# R7FA2E307 register map
Vendor: Renesas Electronics Corporation; Series: RA2; File version: 1.20.00
CPU: CM23 r1p0, little endian, MPU, no FPU, VTOR, 2 interrupt priority bits, 32 interrupts
Registers are 8-bit, read-write, reset 0x0 unless marked. A register's access mark holds for its fields unless they carry their own. Offsets are from the block's base; [hi:lo] are bit positions; {n}, {i} and the like mark numbered series; 'fields as' and 'values as' point back to an identical list.

## RMPU — Renesas Memory Protection Unit
Base 0x40000000
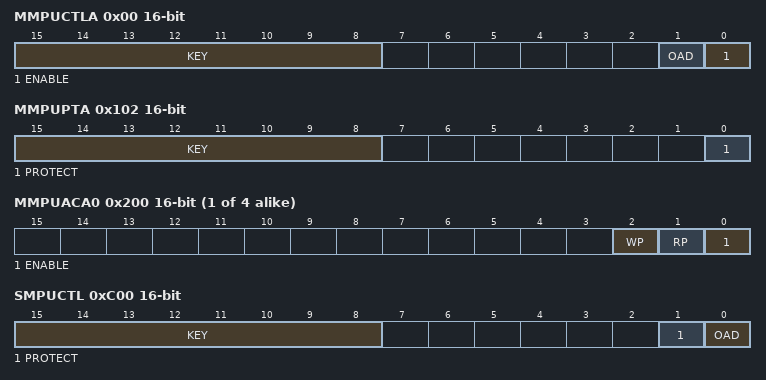
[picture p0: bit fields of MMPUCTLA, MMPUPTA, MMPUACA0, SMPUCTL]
0x00 MMPUCTLA 16-bit — Bus Master MPU Control Register
  [15:8] KEY — Key Code
  [1] OAD — Operation After Detection
  [0] ENABLE — Master Group Enable
0x102 MMPUPTA 16-bit — Group A Protection of Register
  [15:8] KEY — Key Code
  [0] PROTECT — Protection of Register
{0x200+0x10*i} MMPUACA{i} (i=0..3) 16-bit — Group A Region {i} access control register
  [2] WP — Write Protection
  [1] RP — Read Protection
  [0] ENABLE — Region Enable
{0x204+0x10*i} MMPUSA{i} (i=0..3) 32-bit (reset mask 0x3) — Group A Region {i} Start Address Register
  [31:0] MMPUSA — Region Start Address
{0x208+0x10*i} MMPUEA{i} (i=0..3) 32-bit reset 0x3 (reset mask 0x3) — Group A Region {i} End Address Register
  [31:0] MMPUEA — Region End Address
0xC00 SMPUCTL 16-bit — Slave MPU Control Register
  [15:8] KEY — Key Code
  [1] PROTECT — Protection of Register
  [0] OAD — Operation After Detection
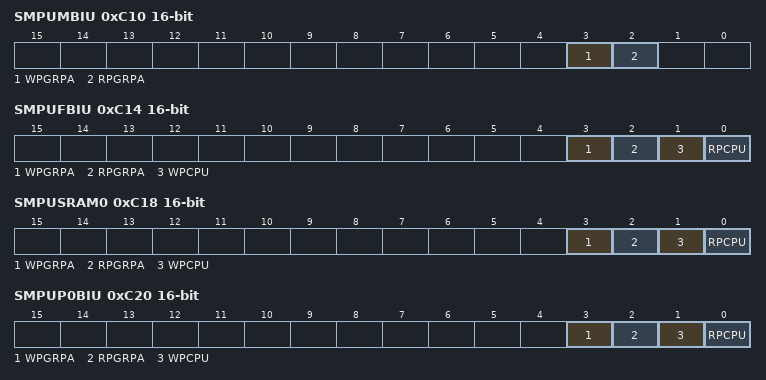
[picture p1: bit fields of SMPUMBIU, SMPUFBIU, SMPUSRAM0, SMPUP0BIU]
0xC10 SMPUMBIU 16-bit — Access Control Register for Memory Bus 1
  [3] WPGRPA — Master MPU Group A Write Protection
  [2] RPGRPA — Master MPU Group A Read Protection
0xC14 SMPUFBIU 16-bit — Access Control Register for Internal Peripheral Bus 9
  [3] WPGRPA — Master MPU Group A Write Protection
  [2] RPGRPA — Master MPU Group A Read Protection
  [1] WPCPU — CPU Write Protection
  [0] RPCPU — CPU Read Protection
0xC18 SMPUSRAM0 16-bit — Access Control Register for Memory Bus 4
  fields as SMPUFBIU
0xC20 SMPUP0BIU 16-bit — Access Control Register for Internal Peripheral Bus 1
  fields as SMPUFBIU
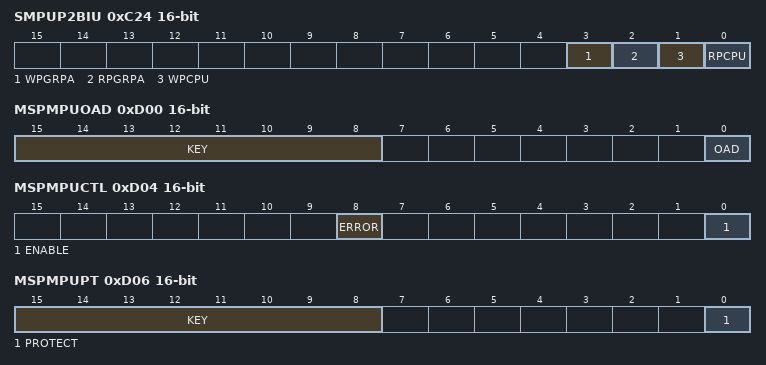
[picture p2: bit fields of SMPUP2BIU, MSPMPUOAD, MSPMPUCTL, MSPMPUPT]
0xC24 SMPUP2BIU 16-bit — Access Control Register for Internal Peripheral Bus 3
  fields as SMPUFBIU
0xD00 MSPMPUOAD 16-bit — Stack Pointer Monitor Operation After Detection Register
  [15:8] KEY — Key Code
  [0] OAD — Operation after Detection
0xD04 MSPMPUCTL 16-bit (reset mask 0xFEFF) — Stack Pointer Monitor Access Control Register
  [8] ERROR — Stack Pointer Monitor Error Flag
  [0] ENABLE — Stack Pointer Monitor Enable
0xD06 MSPMPUPT 16-bit — Stack Pointer Monitor Protection Register
  [15:8] KEY — Key Code
  [0] PROTECT — Protection of Register
0xD08 MSPMPUSA 32-bit reset not defined — Main Stack Pointer (MSP) Monitor Start Address Register
  [31:0] MSPMPUSA range 0x1FF00000..0x200FFFFC — Region Start Address
0xD0C MSPMPUEA 32-bit reset not defined — Main Stack Pointer (MSP) Monitor End Address Register
  [31:0] MSPMPUEA range 0x1FF00003..0x200FFFFF — Region End Address
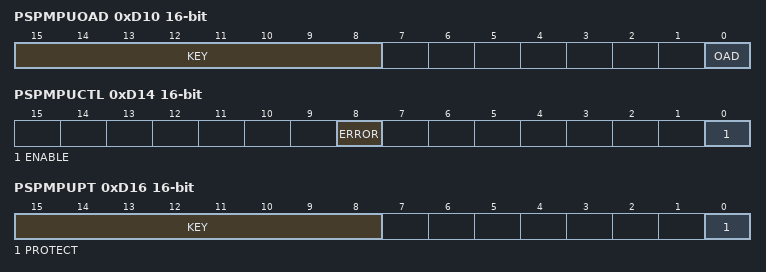
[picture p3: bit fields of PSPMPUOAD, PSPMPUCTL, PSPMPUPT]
0xD10 PSPMPUOAD 16-bit — Stack Pointer Monitor Operation After Detection Register
  [15:8] KEY — Key Code
  [0] OAD — Operation after Detection
0xD14 PSPMPUCTL 16-bit (reset mask 0xFEFF) — Stack Pointer Monitor Access Control Register
  fields as MSPMPUCTL
0xD16 PSPMPUPT 16-bit — Stack Pointer Monitor Protection Register
  [15:8] KEY — Key Code
  [0] PROTECT — Protection of Register
0xD18 PSPMPUSA 32-bit reset not defined — Process Stack Pointer (PSP) Monitor Start Address Register
  [31:0] PSPMPUSA range 0x1FF00000..0x200FFFFC — Region Start Address
0xD1C PSPMPUEA 32-bit reset not defined — Process Stack Pointer (PSP) Monitor End Address Register
  [31:0] PSPMPUEA range 0x1FF00003..0x200FFFFF — Region End Address

## SRAM — SRAM Control
Base 0x40002000
0x00 PARIOAD — SRAM Parity Error Operation After Detection Register
  [0] OAD — Operation After Detection
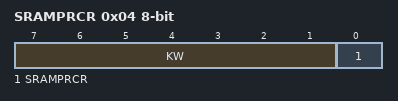
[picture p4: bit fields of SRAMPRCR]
0x04 SRAMPRCR — SRAM Protection Register
  [7:1] KW wo — Write Key Code
  [0] SRAMPRCR — Register Write Control

## BUS — BUS Control
Base 0x40003000
0x1008 BUSMCNTSYS 16-bit — Master Bus Control Register SYS
  [15] IERES — Ignore Error Responses
0x100C BUSMCNTDMA 16-bit — Master Bus Control Register DMA
  [15] IERES — Ignore Error Responses
0x1820 BUS3ERRADD 32-bit ro reset not defined — Bus Error Address Register 3
  [31:0] BERAD — Bus Error Address
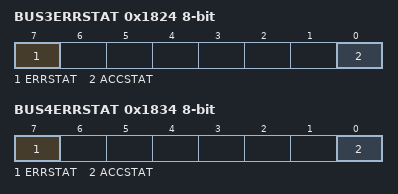
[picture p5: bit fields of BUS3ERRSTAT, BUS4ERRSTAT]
0x1824 BUS3ERRSTAT ro (reset mask 0xFE) — BUS Error Status Register 3
  [7] ERRSTAT — Bus Error Status flag
  [0] ACCSTAT — Error Access Status flag
0x1830 BUS4ERRADD 32-bit ro reset not defined — Bus Error Address Register 4
  [31:0] BERAD — Bus Error Address
0x1834 BUS4ERRSTAT ro (reset mask 0xFE) — BUS Error Status Register 4
  fields as BUS3ERRSTAT

## Notices in the file
This software is supplied by Renesas Electronics Corporation and is only intended for
use with Renesas products. No other uses are authorized. This software is owned by
Renesas Electronics Corporation and is protected under all applicable laws, including
copyright laws.
THIS SOFTWARE IS PROVIDED "AS IS" AND RENESAS MAKES NO WARRANTIES REGARDING
THIS SOFTWARE, WHETHER EXPRESS, IMPLIED OR STATUTORY, INCLUDING BUT NOT LIMITED TO
WARRANTIES OF MERCHANTABILITY, FITNESS FOR A PARTICULAR PURPOSE AND NON-INFRINGEMENT.
ALL SUCH WARRANTIES ARE EXPRESSLY DISCLAIMED. TO THE MAXIMUM EXTENT PERMITTED NOT
PROHIBITED BY LAW, NEITHER RENESAS ELECTRONICS CORPORATION NOR ANY OF ITS AFFILIATED
COMPANIES SHALL BE LIABLE FOR ANY DIRECT, INDIRECT, SPECIAL, INCIDENTAL OR CONSEQUENTIAL
DAMAGES FOR ANY REASON RELATED TO THIS SOFTWARE, EVEN IF RENESAS OR ITS AFFILIATES HAVE
BEEN ADVISED OF THE POSSIBILITY OF SUCH DAMAGES.
Renesas reserves the right, without notice, to make changes to this software and to
discontinue the availability of this software. By using this software, you agree to
the additional terms and conditions found by accessing the following link:
http://www.renesas.com/disclaimer
